# STM32H7x7_CM7 register map
File version: 1.0
CPU: CM7 r0p1, little endian, MPU, FPU, 4 interrupt priority bits
Registers are 32-bit, read-write, reset 0x0 unless marked. A register's access mark holds for its fields unless they carry their own. Offsets are from the block's base; [hi:lo] are bit positions; {n}, {i} and the like mark numbered series.

## SWPMI — Single Wire Protocol Master Interface
Base 0x40008800
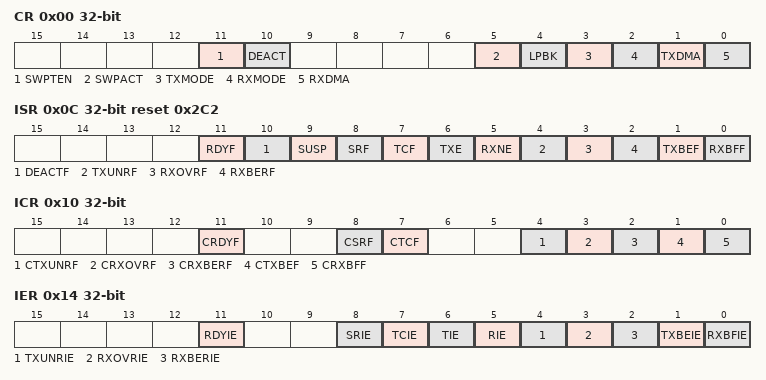
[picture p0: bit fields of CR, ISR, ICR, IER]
0x00 CR — SWPMI Configuration/Control register
  [11] SWPTEN — Single wire protocol master transceiver enable
  [10] DEACT — Single wire protocol master interface deactivate
  [5] SWPACT — Single wire protocol master interface activate
  [4] LPBK — Loopback mode enable
  [3] TXMODE — Transmission buffering mode
  [2] RXMODE — Reception buffering mode
  [1] TXDMA — Transmission DMA enable
  [0] RXDMA — Reception DMA enable
0x04 BRR reset 0x1 — SWPMI Bitrate register
  [7:0] BR — Bitrate prescaler
0x0C ISR ro reset 0x2C2 — SWPMI Interrupt and Status register
  [11] RDYF — transceiver ready flag
  [10] DEACTF — DEACTIVATED flag
  [9] SUSP — SUSPEND flag
  [8] SRF — Slave resume flag
  [7] TCF — Transfer complete flag
  [6] TXE — Transmit data register empty
  [5] RXNE — Receive data register not empty
  [4] TXUNRF — Transmit underrun error flag
  [3] RXOVRF — Receive overrun error flag
  [2] RXBERF — Receive CRC error flag
  [1] TXBEF — Transmit buffer empty flag
  [0] RXBFF — Receive buffer full flag
0x10 ICR wo — SWPMI Interrupt Flag Clear register
  [11] CRDYF — Clear transceiver ready flag
  [8] CSRF — Clear slave resume flag
  [7] CTCF — Clear transfer complete flag
  [4] CTXUNRF — Clear transmit underrun error flag
  [3] CRXOVRF — Clear receive overrun error flag
  [2] CRXBERF — Clear receive CRC error flag
  [1] CTXBEF — Clear transmit buffer empty flag
  [0] CRXBFF — Clear receive buffer full flag
0x14 IER — SWPMI Interrupt Enable register
  [11] RDYIE — Transceiver ready interrupt enable
  [8] SRIE — Slave resume interrupt enable
  [7] TCIE — Transmit complete interrupt enable
  [6] TIE — Transmit interrupt enable
  [5] RIE — Receive interrupt enable
  [4] TXUNRIE — Transmit underrun error interrupt enable
  [3] RXOVRIE — Receive overrun error interrupt enable
  [2] RXBERIE — Receive CRC error interrupt enable
  [1] TXBEIE — Transmit buffer empty interrupt enable
  [0] RXBFIE — Receive buffer full interrupt enable
0x18 RFL ro — SWPMI Receive Frame Length register
  [4:0] RFL — Receive frame length
0x1C TDR wo — SWPMI Transmit data register
  [31:0] TD — Transmit data
0x20 RDR ro — SWPMI Receive data register
  [31:0] RD — received data
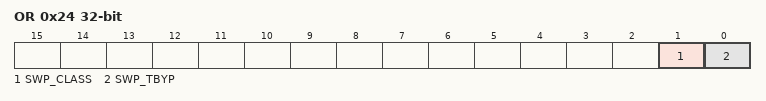
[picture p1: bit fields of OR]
0x24 OR — SWPMI Option register
  [1] SWP_CLASS — SWP class selection
  [0] SWP_TBYP — SWP transceiver bypass

## MPU — Memory protection unit
Base 0xE000ED90
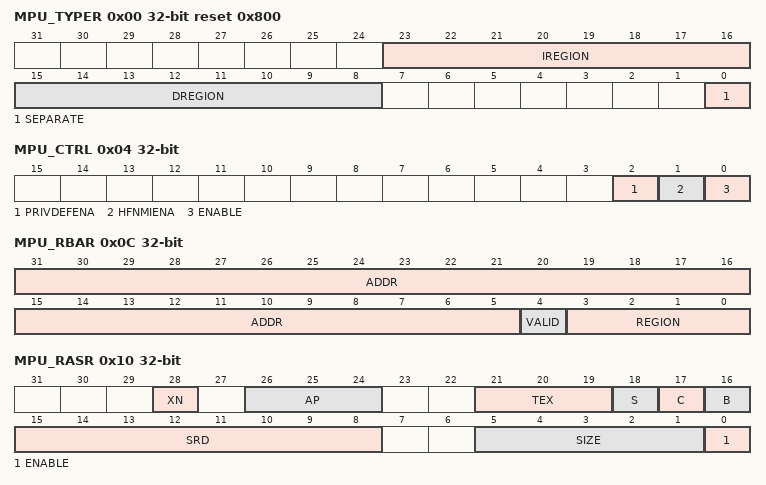
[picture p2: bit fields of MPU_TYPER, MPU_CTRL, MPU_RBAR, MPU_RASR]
0x00 MPU_TYPER ro reset 0x800 — MPU type register
  [23:16] IREGION — Number of MPU instruction regions
  [15:8] DREGION — Number of MPU data regions
  [0] SEPARATE — Separate flag
0x04 MPU_CTRL ro — MPU control register
  [2] PRIVDEFENA — Enable priviliged software access to default memory map
  [1] HFNMIENA — Enables the operation of MPU during hard fault
  [0] ENABLE — Enables the MPU
0x08 MPU_RNR — MPU region number register
  [7:0] REGION — MPU region
0x0C MPU_RBAR — MPU region base address register
  [31:5] ADDR — Region base address field
  [4] VALID — MPU region number valid
  [3:0] REGION — MPU region field
0x10 MPU_RASR — MPU region attribute and size register
  [28] XN — Instruction access disable bit
  [26:24] AP — Access permission
  [21:19] TEX — memory attribute
  [18] S — Shareable memory attribute
  [17] C — memory attribute
  [16] B — memory attribute
  [15:8] SRD — Subregion disable bits
  [5:1] SIZE — Size of the MPU protection region
  [0] ENABLE — Region enable bit.

## STK — SysTick timer
Base 0xE000E010
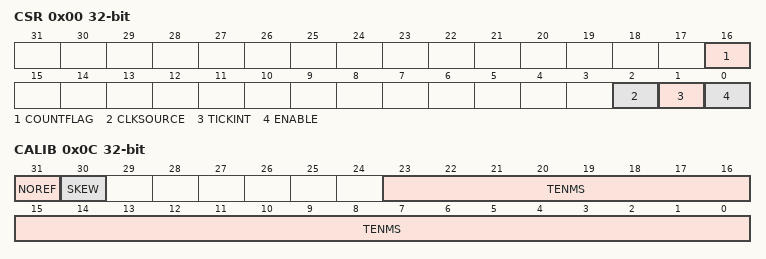
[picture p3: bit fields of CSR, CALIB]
0x00 CSR — SysTick control and status register
  [16] COUNTFLAG
  [2] CLKSOURCE — Clock source selection
  [1] TICKINT — SysTick exception request enable
  [0] ENABLE — Counter enable
0x04 RVR — SysTick reload value register
  [23:0] RELOAD — RELOAD value
0x08 CVR — SysTick current value register
  [23:0] CURRENT — Current counter value
0x0C CALIB — SysTick calibration value register
  [31] NOREF — NOREF flag. Reads as zero
  [30] SKEW — SKEW flag: Indicates whether the TENMS value is exact
  [23:0] TENMS — Calibration value

## SCB — System control block
Base 0xE000ED00
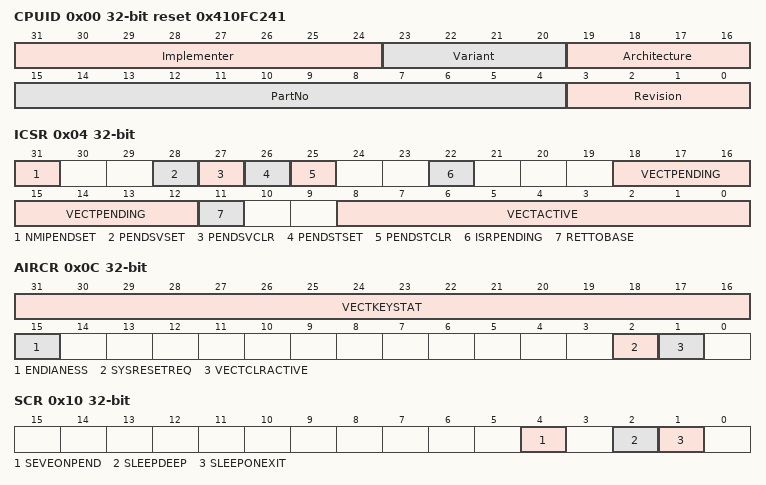
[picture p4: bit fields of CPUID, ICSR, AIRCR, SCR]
0x00 CPUID ro reset 0x410FC241 — CPUID base register
  [31:24] Implementer — Implementer code
  [23:20] Variant — Variant number
  [19:16] Architecture — Reads as 0xF
  [15:4] PartNo — Part number of the processor
  [3:0] Revision — Revision number
0x04 ICSR — Interrupt control and state register
  [31] NMIPENDSET — NMI set-pending bit.
  [28] PENDSVSET — PendSV set-pending bit
  [27] PENDSVCLR — PendSV clear-pending bit
  [26] PENDSTSET — SysTick exception set-pending bit
  [25] PENDSTCLR — SysTick exception clear-pending bit
  [22] ISRPENDING — Interrupt pending flag
  [18:12] VECTPENDING — Pending vector
  [11] RETTOBASE — Return to base level
  [8:0] VECTACTIVE — Active vector
0x08 VTOR — Vector table offset register
  [31:7] TBLOFF — Vector table base offset field
0x0C AIRCR — Application interrupt and reset control register
  [31:16] VECTKEYSTAT — Register key
  [15] ENDIANESS
  [2] SYSRESETREQ
  [1] VECTCLRACTIVE
0x10 SCR — System control register
  [4] SEVEONPEND — Send Event on Pending bit
  [2] SLEEPDEEP
  [1] SLEEPONEXIT
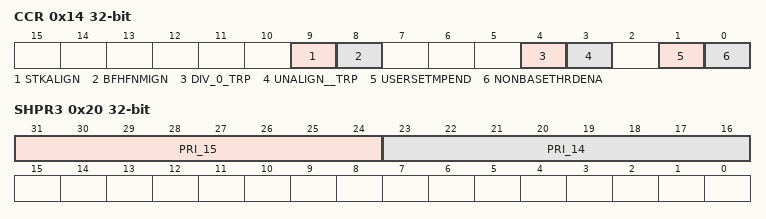
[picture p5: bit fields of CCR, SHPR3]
0x14 CCR — Configuration and control register
  [9] STKALIGN
  [8] BFHFNMIGN
  [4] DIV_0_TRP
  [3] UNALIGN__TRP
  [1] USERSETMPEND
  [0] NONBASETHRDENA — Configures how the processor enters Thread mode
0x1C SHPR2 — System handler priority registers
  [31:24] PRI_11 — Priority of system handler 11
0x20 SHPR3 — System handler priority registers
  [31:24] PRI_15 — Priority of system handler 15
  [23:16] PRI_14 — Priority of system handler 14

## NVIC_STIR — Nested vectored interrupt controller
Base 0xE000EF00
0x00 STIR — Software trigger interrupt register
  [8:0] INTID — Software generated interrupt ID

## FPU_CPACR — Floating point unit CPACR
Base 0xE000ED88
0x00 CPACR — Coprocessor access control register
  [23:20] CP

## SCB_ACTRL — System control block ACTLR
Base 0xE000E008
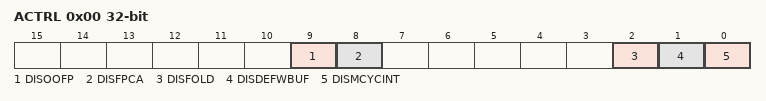
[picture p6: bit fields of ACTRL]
0x00 ACTRL — Auxiliary control register
  [9] DISOOFP, [8] DISFPCA, [2] DISFOLD, [1] DISDEFWBUF, [0] DISMCYCINT

## NVIC — Nested Vectored Interrupt Controller
Base 0xE000E100
0x00 ISER0 — Interrupt Set-Enable Register
  [31:0] SETENA
0x04 ISER1 — Interrupt Set-Enable Register
  [31:0] SETENA
0x80 ICER0 — Interrupt Clear-Enable Register
  [31:0] CLRENA
0x84 ICER1 — Interrupt Clear-Enable Register
  [31:0] CLRENA
0x100 ISPR0 — Interrupt Set-Pending Register
  [31:0] SETPEND
0x104 ISPR1 — Interrupt Set-Pending Register
  [31:0] SETPEND
0x180 ICPR0 — Interrupt Clear-Pending Register
  [31:0] CLRPEND
0x184 ICPR1 — Interrupt Clear-Pending Register
  [31:0] CLRPEND
0x200 IABR0 ro — Interrupt Active Bit Register
  [31:0] ACTIVE
0x204 IABR1 ro — Interrupt Active Bit Register
  [31:0] ACTIVE
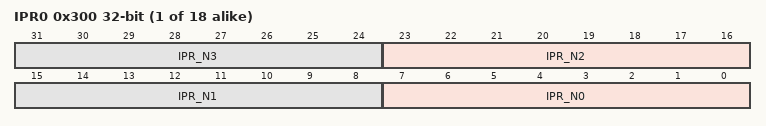
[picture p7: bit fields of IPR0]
{0x300+4i} IPR{i} (i=0..17) — Interrupt Priority Register
  [8n+7:8n] IPR_N{n} (n=0..3)
